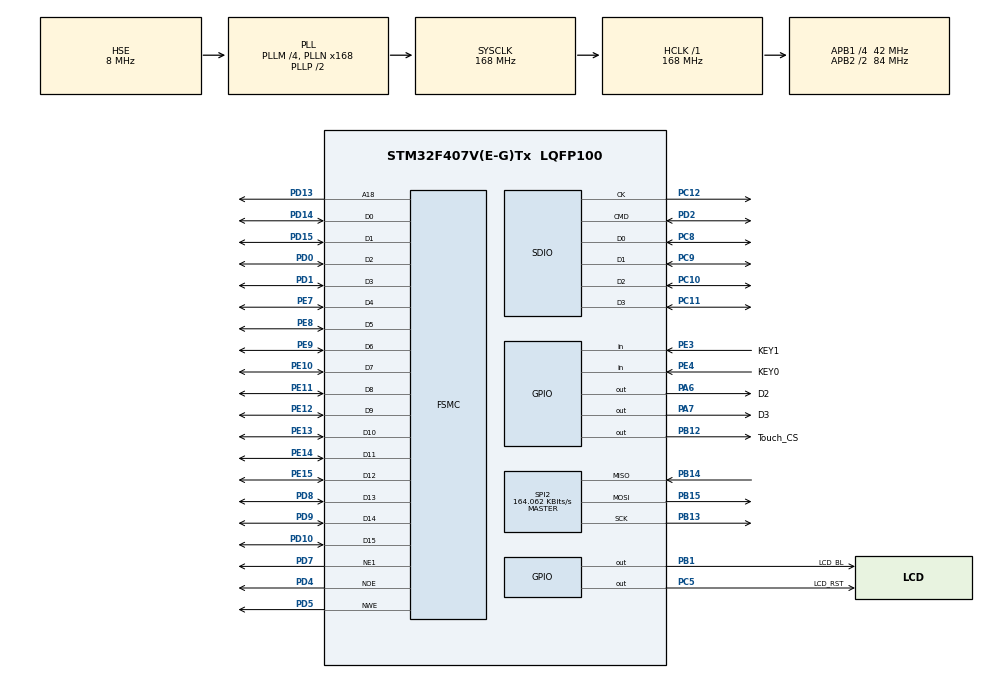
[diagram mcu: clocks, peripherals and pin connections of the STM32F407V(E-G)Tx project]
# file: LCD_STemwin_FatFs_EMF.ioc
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FATFS.USE_DMA_CODE_SD=0
FATFS._CODE_PAGE=936
FATFS._USE_FASTSEEK=0
FATFS._USE_FIND=0
FATFS._USE_LFN=2
FSMC.AddressSetupTime1=4
FSMC.BusTurnAroundDuration1=0
FSMC.DataSetupTime1=10
Mcu.Family=STM32F4
Mcu.Name=STM32F407V(E-G)Tx
Mcu.Package=LQFP100
NVIC.PriorityGroup=NVIC_PRIORITYGROUP_4
PA13.Mode=Serial_Wire
PA13.Signal=SYS_JTMS-SWDIO
PA14.Mode=Serial_Wire
PA14.Signal=SYS_JTCK-SWCLK
PA6.GPIO_Label=D2
PA6.GPIO_Speed=GPIO_SPEED_FREQ_VERY_HIGH
PA6.Signal=GPIO_Output
PA7.GPIO_Label=D3
PA7.GPIO_Speed=GPIO_SPEED_FREQ_VERY_HIGH
PA7.Signal=GPIO_Output
PB1.GPIO_Label=LCD_BL
PB1.GPIO_Speed=GPIO_SPEED_FREQ_VERY_HIGH
PB1.Signal=GPIO_Output
PB12.GPIO_Label=Touch_CS
PB12.GPIO_Speed=GPIO_SPEED_FREQ_VERY_HIGH
PB12.Signal=GPIO_Output
PB13.Mode=Full_Duplex_Master
PB13.Signal=SPI2_SCK
PB14.Mode=Full_Duplex_Master
PB14.Signal=SPI2_MISO
PB15.Mode=Full_Duplex_Master
PB15.Signal=SPI2_MOSI
PC10.Mode=SD_4_bits_Wide_bus
PC10.Signal=SDIO_D2
PC11.Mode=SD_4_bits_Wide_bus
PC11.Signal=SDIO_D3
PC12.Mode=SD_4_bits_Wide_bus
PC12.Signal=SDIO_CK
PC14-OSC32_IN.Mode=LSE-External-Oscillator
PC14-OSC32_IN.Signal=RCC_OSC32_IN
PC15-OSC32_OUT.Mode=LSE-External-Oscillator
PC15-OSC32_OUT.Signal=RCC_OSC32_OUT
PC5.GPIO_Label=LCD_RST
PC5.GPIO_Speed=GPIO_SPEED_FREQ_VERY_HIGH
PC5.Signal=GPIO_Output
PC8.Mode=SD_4_bits_Wide_bus
PC8.Signal=SDIO_D0
PC9.Mode=SD_4_bits_Wide_bus
PC9.Signal=SDIO_D1
PD0.Mode=16b-d1
PD0.Signal=FSMC_D2
PD1.Mode=16b-d1
PD1.Signal=FSMC_D3
PD10.Mode=16b-d1
PD10.Signal=FSMC_D15
PD13.Mode=A18_1
PD13.Signal=FSMC_A18
PD14.Mode=16b-d1
PD14.Signal=FSMC_D0
PD15.Mode=16b-d1
PD15.Signal=FSMC_D1
PD2.Mode=SD_4_bits_Wide_bus
PD2.Signal=SDIO_CMD
PD4.Mode=Lcd1
PD4.Signal=FSMC_NOE
PD5.Mode=Lcd1
PD5.Signal=FSMC_NWE
PD7.Mode=NorPsramChipSelect1_1
PD7.Signal=FSMC_NE1
PD8.Mode=16b-d1
PD8.Signal=FSMC_D13
PD9.Mode=16b-d1
PD9.Signal=FSMC_D14
PE10.Mode=16b-d1
PE10.Signal=FSMC_D7
PE11.Mode=16b-d1
PE11.Signal=FSMC_D8
PE12.Mode=16b-d1
PE12.Signal=FSMC_D9
PE13.Mode=16b-d1
PE13.Signal=FSMC_D10
PE14.Mode=16b-d1
PE14.Signal=FSMC_D11
PE15.Mode=16b-d1
PE15.Signal=FSMC_D12
PE3.GPIO_Label=KEY1
PE3.Signal=GPIO_Input
PE4.GPIO_Label=KEY0
PE4.Signal=GPIO_Input
PE7.Mode=16b-d1
PE7.Signal=FSMC_D4
PE8.Mode=16b-d1
PE8.Signal=FSMC_D5
PE9.Mode=16b-d1
PE9.Signal=FSMC_D6
PH0-OSC_IN.Mode=HSE-External-Oscillator
PH0-OSC_IN.Signal=RCC_OSC_IN
PH1-OSC_OUT.Mode=HSE-External-Oscillator
PH1-OSC_OUT.Signal=RCC_OSC_OUT
ProjectManager.HeapSize=0x1000
ProjectManager.StackSize=0x1200
ProjectManager.TargetToolchain=EWARM V8
RCC.48MHZClocksFreq_Value=48000000
RCC.AHBFreq_Value=168000000
RCC.APB1CLKDivider=RCC_HCLK_DIV4
RCC.APB1Freq_Value=42000000
RCC.APB1TimFreq_Value=84000000
RCC.APB2CLKDivider=RCC_HCLK_DIV2
RCC.APB2Freq_Value=84000000
RCC.APB2TimFreq_Value=168000000
RCC.CortexFreq_Value=168000000
RCC.EnbaleCSS=true
RCC.HCLKFreq_Value=168000000
RCC.HSE_VALUE=8000000
RCC.HSI_VALUE=16000000
RCC.PLLM=4
RCC.PLLN=168
RCC.PLLQ=7
RCC.PLLSourceVirtual=RCC_PLLSOURCE_HSE
RCC.SYSCLKFreq_VALUE=168000000
RCC.SYSCLKSource=RCC_SYSCLKSOURCE_PLLCLK
RCC.VCOOutputFreq_Value=336000000
SPI2.BaudRatePrescaler=SPI_BAUDRATEPRESCALER_256
SPI2.CLKPhase=SPI_PHASE_1EDGE
SPI2.CLKPolarity=SPI_POLARITY_LOW
SPI2.CalculateBaudRate=164.062 KBits/s
SPI2.Direction=SPI_DIRECTION_2LINES
SPI2.Mode=SPI_MODE_MASTER
SPI2.VirtualType=VM_MASTER
VP_CRC_VS_CRC.Mode=CRC_Activate
VP_FATFS_VS_SDIO.Mode=SDIO
board=LCD_Drive

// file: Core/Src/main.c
/* USER CODE BEGIN Header */
/**
  ******************************************************************************
  * @file           : main.c
  * @brief          : Main program body
  ******************************************************************************
  * @attention
  *
  * <h2><center>&copy; Copyright (c) 2019 STMicroelectronics.
  * All rights reserved.</center></h2>
  *
  * This software component is licensed by ST under Ultimate Liberty license
  * SLA0044, the "License"; You may not use this file except in compliance with
  * the License. You may obtain a copy of the License at:
  *                             www.st.com/SLA0044
  *
  ******************************************************************************
  */
/* USER CODE END Header */

#include "main.h"
#include "crc.h"
#include "fatfs.h"
#include "sdio.h"
#include "spi.h"
#include "gpio.h"
#include "fsmc.h"

/* USER CODE BEGIN Includes */
#include "gui.h"
/* USER CODE END Includes */

void SystemClock_Config(void);

int main(void)
{

  /* MCU Configuration--------------------------------------------------------*/

  /* Reset of all peripherals, Initializes the Flash interface and the Systick. */
  HAL_Init();

  /* Configure the system clock */
  SystemClock_Config();

  /* Initialize all configured peripherals */
  MX_GPIO_Init();
  MX_FSMC_Init();
  MX_CRC_Init();
  MX_SPI2_Init();
  MX_SDIO_SD_Init();
  MX_FATFS_Init();

  /* Infinite loop */
  while (1)
  {

  }
}

void SystemClock_Config(void)
{
  RCC_OscInitTypeDef RCC_OscInitStruct = {0};
  RCC_ClkInitTypeDef RCC_ClkInitStruct = {0};

  /** Configure the main internal regulator output voltage
  */
  __HAL_RCC_PWR_CLK_ENABLE();
  __HAL_PWR_VOLTAGESCALING_CONFIG(PWR_REGULATOR_VOLTAGE_SCALE1);
  /** Initializes the CPU, AHB and APB busses clocks
  */
  RCC_OscInitStruct.OscillatorType = RCC_OSCILLATORTYPE_HSE;
  RCC_OscInitStruct.HSEState = RCC_HSE_ON;
  RCC_OscInitStruct.PLL.PLLState = RCC_PLL_ON;
  RCC_OscInitStruct.PLL.PLLSource = RCC_PLLSOURCE_HSE;
  RCC_OscInitStruct.PLL.PLLM = 4;
  RCC_OscInitStruct.PLL.PLLN = 168;
  RCC_OscInitStruct.PLL.PLLP = RCC_PLLP_DIV2;
  RCC_OscInitStruct.PLL.PLLQ = 7;
  if (HAL_RCC_OscConfig(&RCC_OscInitStruct) != HAL_OK)
  {
    Error_Handler();
  }
  /** Initializes the CPU, AHB and APB busses clocks
  */
  RCC_ClkInitStruct.ClockType = RCC_CLOCKTYPE_HCLK|RCC_CLOCKTYPE_SYSCLK
                              |RCC_CLOCKTYPE_PCLK1|RCC_CLOCKTYPE_PCLK2;
  RCC_ClkInitStruct.SYSCLKSource = RCC_SYSCLKSOURCE_PLLCLK;
  RCC_ClkInitStruct.AHBCLKDivider = RCC_SYSCLK_DIV1;
  RCC_ClkInitStruct.APB1CLKDivider = RCC_HCLK_DIV4;
  RCC_ClkInitStruct.APB2CLKDivider = RCC_HCLK_DIV2;

  if (HAL_RCC_ClockConfig(&RCC_ClkInitStruct, FLASH_LATENCY_5) != HAL_OK)
  {
    Error_Handler();
  }
  /** Enables the Clock Security System
  */
  HAL_RCC_EnableCSS();
}

void Error_Handler(void)
{
}

/************************ (C) COPYRIGHT STMicroelectronics *****END OF FILE****/
